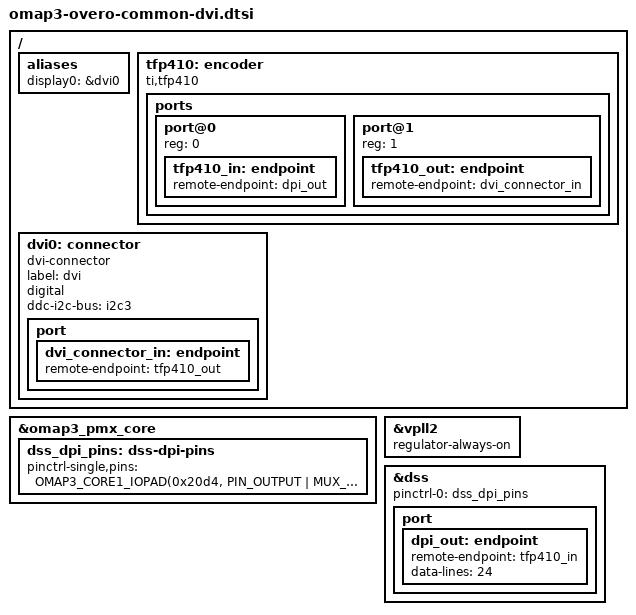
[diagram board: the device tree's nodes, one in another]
&omap3_pmx_core {
	dss_dpi_pins: dss-dpi-pins {
		pinctrl-single,pins = <
			OMAP3_CORE1_IOPAD(0x20d4, PIN_OUTPUT | MUX_MODE0)	 
			OMAP3_CORE1_IOPAD(0x20d6, PIN_OUTPUT | MUX_MODE0)	 
			OMAP3_CORE1_IOPAD(0x20d8, PIN_OUTPUT | MUX_MODE0)	 
			OMAP3_CORE1_IOPAD(0x20da, PIN_OUTPUT | MUX_MODE0)	 
			OMAP3_CORE1_IOPAD(0x20dc, PIN_OUTPUT | MUX_MODE0)	 
			OMAP3_CORE1_IOPAD(0x20de, PIN_OUTPUT | MUX_MODE0)	 
			OMAP3_CORE1_IOPAD(0x20e0, PIN_OUTPUT | MUX_MODE0)	 
			OMAP3_CORE1_IOPAD(0x20e2, PIN_OUTPUT | MUX_MODE0)	 
			OMAP3_CORE1_IOPAD(0x20e4, PIN_OUTPUT | MUX_MODE0)	 
			OMAP3_CORE1_IOPAD(0x20e6, PIN_OUTPUT | MUX_MODE0)	 
			OMAP3_CORE1_IOPAD(0x20e8, PIN_OUTPUT | MUX_MODE0)	 
			OMAP3_CORE1_IOPAD(0x20ea, PIN_OUTPUT | MUX_MODE0)	 
			OMAP3_CORE1_IOPAD(0x20ec, PIN_OUTPUT | MUX_MODE0)	 
			OMAP3_CORE1_IOPAD(0x20ee, PIN_OUTPUT | MUX_MODE0)	 
			OMAP3_CORE1_IOPAD(0x20f0, PIN_OUTPUT | MUX_MODE0)	 
			OMAP3_CORE1_IOPAD(0x20f2, PIN_OUTPUT | MUX_MODE0)	 
			OMAP3_CORE1_IOPAD(0x20f4, PIN_OUTPUT | MUX_MODE0)	 
			OMAP3_CORE1_IOPAD(0x20f6, PIN_OUTPUT | MUX_MODE0)	 
			OMAP3_CORE1_IOPAD(0x20f8, PIN_OUTPUT | MUX_MODE0)	 
			OMAP3_CORE1_IOPAD(0x20fa, PIN_OUTPUT | MUX_MODE0)	 
			OMAP3_CORE1_IOPAD(0x20fc, PIN_OUTPUT | MUX_MODE0)	 
			OMAP3_CORE1_IOPAD(0x20fe, PIN_OUTPUT | MUX_MODE0)	 
			OMAP3_CORE1_IOPAD(0x2100, PIN_OUTPUT | MUX_MODE0)	 
			OMAP3_CORE1_IOPAD(0x2102, PIN_OUTPUT | MUX_MODE0)	 
			OMAP3_CORE1_IOPAD(0x2104, PIN_OUTPUT | MUX_MODE0)	 
			OMAP3_CORE1_IOPAD(0x2106, PIN_OUTPUT | MUX_MODE0)	 
			OMAP3_CORE1_IOPAD(0x2108, PIN_OUTPUT | MUX_MODE0)	 
			OMAP3_CORE1_IOPAD(0x210a, PIN_OUTPUT | MUX_MODE0)	 
		>;
	};
};
&vpll2 {
	regulator-always-on;
};
&dss {
	status = "okay";
	pinctrl-names = "default";
	pinctrl-0 = <&dss_dpi_pins>;
	port {
		dpi_out: endpoint {
			remote-endpoint = <&tfp410_in>;
			data-lines = <24>;
		};
	};
};
/ {
	aliases {
		display0 = &dvi0;
	};
	tfp410: encoder {
		compatible = "ti,tfp410";
		ports {
			#address-cells = <1>;
			#size-cells = <0>;
			port@0 {
				reg = <0>;
				tfp410_in: endpoint {
					remote-endpoint = <&dpi_out>;
				};
			};
			port@1 {
				reg = <1>;
				tfp410_out: endpoint {
					remote-endpoint = <&dvi_connector_in>;
				};
			};
		};
	};
	dvi0: connector {
		compatible = "dvi-connector";
		label = "dvi";
		digital;
		ddc-i2c-bus = <&i2c3>;
		port {
			dvi_connector_in: endpoint {
				remote-endpoint = <&tfp410_out>;
			};
		};
	};
};
